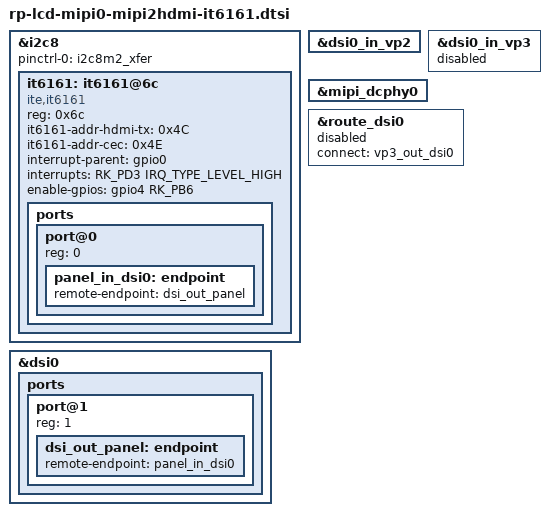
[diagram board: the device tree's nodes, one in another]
&i2c8 {
    status = "okay";
    pinctrl-names = "default";
    pinctrl-0 = <&i2c8m2_xfer>;
    
    /*
    ite6161 max output 1080p@p60Hz
    dsi1->vp3(max 1080p@p60Hz)->ite6161->card0-HDMI-A-4
    */
   	it6161: it6161@6c {
		status = "okay";
		compatible = "ite,it6161";
		#sound-dai-cells = <0>;
		reg = <0x6c>;
		it6161-addr-hdmi-tx = <0x4C>;
		it6161-addr-cec = <0x4E>;
		interrupt-parent = <&gpio0>;
		interrupts = <RK_PD3 IRQ_TYPE_LEVEL_HIGH>;
		enable-gpios = <&gpio4 RK_PB6 GPIO_ACTIVE_HIGH>;

		ports {
			#address-cells = <1>;
			#size-cells = <0>;
			port@0 {
				reg = <0>;
				panel_in_dsi0: endpoint {
					remote-endpoint = <&dsi_out_panel>;
				};
			};
		};
	}; 
};

&dsi0 {
    status = "okay";
    ports {
        #address-cells = <1>;
        #size-cells = <0>;

        port@1 {
            reg = <1>;
            dsi_out_panel: endpoint {
                remote-endpoint = <&panel_in_dsi0>;
            };
        };
    };
};


&dsi0_in_vp2 {
    status = "okay";
};

&dsi0_in_vp3 {
    status = "disabled";
};

&mipi_dcphy0 {
    status = "okay";
};

// ite6161 not have uboot driver, don't enable display logo
&route_dsi0 {
    status = "disabled";
    connect = <&vp3_out_dsi0>;
};
